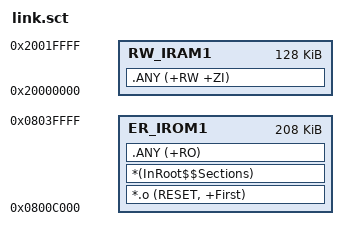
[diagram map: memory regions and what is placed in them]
; *************************************************************
; *** Scatter-Loading Description File generated by uVision ***
; *************************************************************

; APP 208KB @ 0x0800C000
LR_IROM1 0x0800C000 0x00034000  {
  ER_IROM1 0x0800C000 0x00034000  {
   *.o (RESET, +First)
   *(InRoot$$Sections)
   .ANY (+RO)
  }
  RW_IRAM1 0x20000000 0x00020000  {  ; RW data
   .ANY (+RW +ZI)
  }
}

